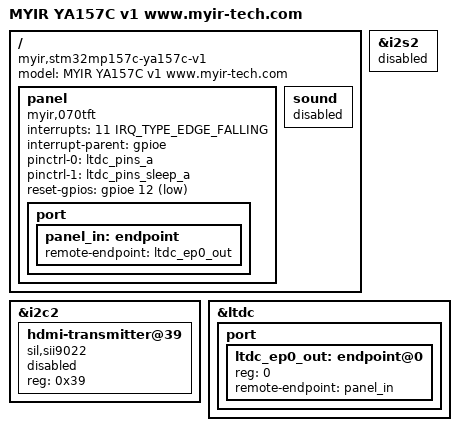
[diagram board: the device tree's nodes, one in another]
// SPDX-License-Identifier: (GPL-2.0+ OR BSD-3-Clause)
/*
* Copyright (C) MYIR 2019 - All Rights Reserved
* Author: myir
* support:support.cn@myirtech.com 
*/

/dts-v1/;

#include "stm32mp157c-ya157c-hdmi-v1.dts"

/ {
    	model = "MYIR YA157C v1 www.myir-tech.com";
    	compatible = "myir,stm32mp157c-ya157c-v1", "st,stm32mp157";

	/*LCD Panel*/
	panel {
		compatible = "myir,070tft";
        	interrupts = <11 IRQ_TYPE_EDGE_FALLING>;
        	interrupt-parent = <&gpioe>;
        	pinctrl-names = "default", "sleep";
        	pinctrl-0 = <&ltdc_pins_a>;
        	pinctrl-1 = <&ltdc_pins_sleep_a>;
        	reset-gpios = <&gpioe 12 GPIO_ACTIVE_LOW>;

		//backlight = <&panel_backlight>;
       	 	status = "okay";
		
		port {
			panel_in: endpoint {
				remote-endpoint = <&ltdc_ep0_out>;			
			};
	
		};
	};
	
	sound {
        	status = "disable";
    	};
	

};

/*HDMI*/
&i2c2 {
	hdmi-transmitter@39 {
		compatible = "sil,sii9022";
		reg = <0x39>;
		status = "disable";
	};
};

&i2s2 {
	status = "disable";

};

/*test LCD*/
&ltdc {
        status = "okay";

        port {
                #address-cells = <1>;
                #size-cells = <0>;

                ltdc_ep0_out: endpoint@0 {
                                reg = <0>;
                                remote-endpoint = <&panel_in>;
                                };
           };
};



